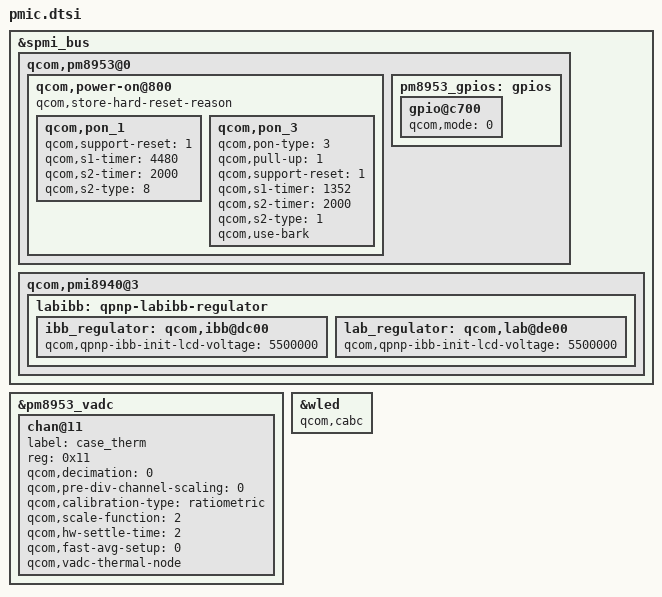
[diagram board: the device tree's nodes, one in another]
/* msm-pm8953 */
&spmi_bus {
	qcom,pm8953@0 {
		qcom,power-on@800 {
			qcom,store-hard-reset-reason;
			qcom,pon_1 {
				qcom,support-reset = <1>;
				qcom,s1-timer = <4480>;
				qcom,s2-timer = <2000>;
				qcom,s2-type = <8>;
			};

			qcom,pon_3 {
				qcom,pon-type = <3>;
				qcom,pull-up = <1>;
				qcom,support-reset = <1>;
				qcom,s1-timer = <1352>;
				qcom,s2-timer = <2000>;
				qcom,s2-type = <1>;
				qcom,use-bark;
			};
		};
		pm8953_gpios: gpios {
			gpio@c700 {
				qcom,mode = <0>;
				status = "ok";
			};
		};
	};
};

&pm8953_vadc {
	/delete-node/ chan@13;
};

&pm8953_vadc {
chan@11 {
		label = "case_therm";
		reg = <0x11>;
		qcom,decimation = <0>;
		qcom,pre-div-channel-scaling = <0>;
		qcom,calibration-type = "ratiometric";
		qcom,scale-function = <2>;
		qcom,hw-settle-time = <2>;
		qcom,fast-avg-setup = <0>;
		qcom,vadc-thermal-node;
	};
};	

&spmi_bus {
	qcom,pmi8940@3 {
		labibb: qpnp-labibb-regulator {
			status = "ok";
			ibb_regulator: qcom,ibb@dc00 {
				/delete-property/
					qcom,qpnp-ibb-use-default-voltage;
				qcom,qpnp-ibb-init-lcd-voltage = <5500000>;
			};

			lab_regulator: qcom,lab@de00 {
				/delete-property/
					qcom,qpnp-ibb-use-default-voltage;
				qcom,qpnp-ibb-init-lcd-voltage = <5500000>;
			};
		};
	};
};

&wled {
	qcom,cabc;
};
